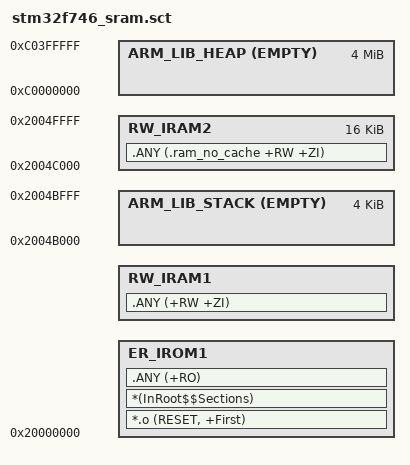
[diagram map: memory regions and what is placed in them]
;*******************************************************************
;* STM32F746 linker scatter file (running code from internal SRAM) *
;*******************************************************************

LR_IROM1 0x20000000 0x50000
{
   ER_IROM1 0x20000000
   {
      *.o (RESET, +First)
      *(InRoot$$Sections)
      .ANY (+RO)
   }
   
   RW_IRAM1 +0
   { 
      .ANY (+RW +ZI)
   }
   
   ScatterAssert((ImageLength(ER_IROM1) + ImageLength(RW_IRAM1)) < 0x4B000)
   
   ARM_LIB_STACK 0x2004C000 EMPTY -0x1000
   {
   }
   
   RW_IRAM2 0x2004C000 0x4000
   {
      .ANY (.ram_no_cache +RW +ZI)
   }
   
   ARM_LIB_HEAP 0xC0000000 EMPTY 0x400000
   {
   }
}
